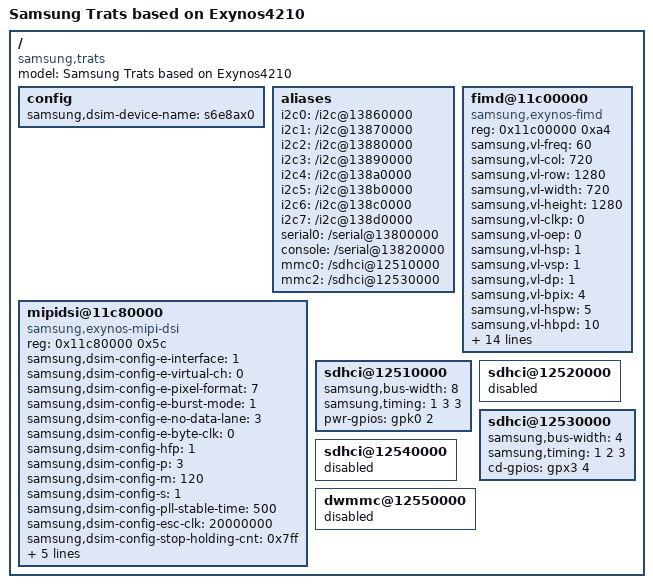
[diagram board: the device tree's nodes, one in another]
/*
 * Samsung's Exynos4210 based Trats board device tree source
 *
 * Copyright (c) 2014 Samsung Electronics Co., Ltd.
 *		http://www.samsung.com
 *
 * SPDX-License-Identifier:	GPL-2.0+
 */

/dts-v1/;
#include "exynos4210.dtsi"

/ {
	model = "Samsung Trats based on Exynos4210";
	compatible = "samsung,trats", "samsung,exynos4210";

	config {
		samsung,dsim-device-name = "s6e8ax0";
	};

	aliases {
		i2c0 = "/i2c@13860000";
		i2c1 = "/i2c@13870000";
		i2c2 = "/i2c@13880000";
		i2c3 = "/i2c@13890000";
		i2c4 = "/i2c@138a0000";
		i2c5 = "/i2c@138b0000";
		i2c6 = "/i2c@138c0000";
		i2c7 = "/i2c@138d0000";
		serial0 = "/serial@13800000";
		console = "/serial@13820000";
		mmc0 = "/sdhci@12510000";
		mmc2 = "/sdhci@12530000";
	};

	fimd@11c00000 {
		compatible = "samsung,exynos-fimd";
		reg = <0x11c00000 0xa4>;

		samsung,vl-freq = <60>;
		samsung,vl-col = <720>;
		samsung,vl-row = <1280>;
		samsung,vl-width = <720>;
		samsung,vl-height = <1280>;

		samsung,vl-clkp = <0>;
		samsung,vl-oep = <0>;
		samsung,vl-hsp = <1>;
		samsung,vl-vsp = <1>;
		samsung,vl-dp = <1>;
		samsung,vl-bpix = <4>;

		samsung,vl-hspw = <5>;
		samsung,vl-hbpd = <10>;
		samsung,vl-hfpd = <10>;
		samsung,vl-vspw = <2>;
		samsung,vl-vbpd = <1>;
		samsung,vl-vfpd = <13>;
		samsung,vl-cmd-allow-len = <0xf>;

		samsung,winid = <3>;
		samsung,power-on-delay = <30>;
		samsung,interface-mode = <1>;
		samsung,mipi-enabled = <1>;
		samsung,dp-enabled;
		samsung,dual-lcd-enabled;

		samsung,logo-on = <1>;
		samsung,resolution = <0>;
		samsung,rgb-mode = <0>;
	};

	mipidsi@11c80000 {
		compatible = "samsung,exynos-mipi-dsi";
		reg = <0x11c80000 0x5c>;

		samsung,dsim-config-e-interface = <1>;
		samsung,dsim-config-e-virtual-ch = <0>;
		samsung,dsim-config-e-pixel-format = <7>;
		samsung,dsim-config-e-burst-mode = <1>;
		samsung,dsim-config-e-no-data-lane = <3>;
		samsung,dsim-config-e-byte-clk = <0>;
		samsung,dsim-config-hfp = <1>;

		samsung,dsim-config-p = <3>;
		samsung,dsim-config-m = <120>;
		samsung,dsim-config-s = <1>;

		samsung,dsim-config-pll-stable-time = <500>;
		samsung,dsim-config-esc-clk = <20000000>;
		samsung,dsim-config-stop-holding-cnt = <0x7ff>;
		samsung,dsim-config-bta-timeout = <0xff>;
		samsung,dsim-config-rx-timeout = <0xffff>;

		samsung,dsim-device-id = <0xffffffff>;
		samsung,dsim-device-bus-id = <0>;

		samsung,dsim-device-reverse-panel = <1>;
	};

	sdhci@12510000 {
		samsung,bus-width = <8>;
		samsung,timing = <1 3 3>;
		pwr-gpios = <&gpk0 2 0>;
	};

	sdhci@12520000 {
		status = "disabled";
	};

	sdhci@12530000 {
		samsung,bus-width = <4>;
		samsung,timing = <1 2 3>;
		cd-gpios = <&gpx3 4 0>;
	};

	sdhci@12540000 {
		status = "disabled";
	};

	dwmmc@12550000 {
		status = "disabled";
	};
};
